# RS14100 register map
File version: 1.0
CPU: CM4 r0p1, little endian, MPU, FPU, 4 interrupt priority bits
Registers are 32-bit, read-write, reset 0x0 unless marked. A register's access mark holds for its fields unless they carry their own. Offsets are from the block's base; [hi:lo] are bit positions; lines under a group give offsets from that group; {n}, {i} and the like mark numbered series; 'fields as' and 'values as' point back to an identical list.

## MCPWM — The Motor Control PWM (MCPWM) controller is used to generate a periodic pulse waveform, which is useful in motor control and power control applications
Base 0x47070000
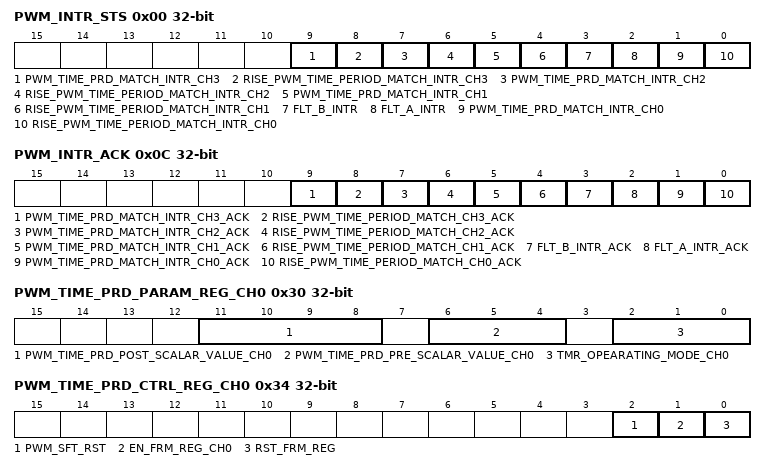
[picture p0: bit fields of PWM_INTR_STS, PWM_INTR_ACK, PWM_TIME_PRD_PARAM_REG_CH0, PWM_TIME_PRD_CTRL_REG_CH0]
0x00 PWM_INTR_STS ro — PWM Interrupt Status Register
  [9] PWM_TIME_PRD_MATCH_INTR_CH3 — This time base interrupt for 3rd channel, which considers postscaler value.
  [8] RISE_PWM_TIME_PERIOD_MATCH_INTR_CH3 — This time base interrupt for 3rd channel without considering postscaler value.
  [7] PWM_TIME_PRD_MATCH_INTR_CH2 — This time base interrupt for 2nd channel, which considers postscaler value
  [6] RISE_PWM_TIME_PERIOD_MATCH_INTR_CH2 — This time base interrupt for 2nd channel without considering postscaler value.
  [5] PWM_TIME_PRD_MATCH_INTR_CH1 — This time base interrupt for 1st channel, which considers postscaler value.
  [4] RISE_PWM_TIME_PERIOD_MATCH_INTR_CH1 — This time base interrupt for 1st channel without considering postscaler value
  [3] FLT_B_INTR — When the fault B pin is driven low, this interrupt is raised.
  [2] FLT_A_INTR — When the fault A pin is driven low, this interrupt is raised.
  [1] PWM_TIME_PRD_MATCH_INTR_CH0 — This time base interrupt for 0th channel, which considers postscaler value
  [0] RISE_PWM_TIME_PERIOD_MATCH_INTR_CH0 — This time base interrupt for 0th channel without considering postscaler
0x04 PWM_INTR_UNMASK — PWM Interrupt Unmask Register
  [15:0] PWM_INTR_UNMASK
0x08 PWM_INTR_MASK — PWM Interrupt mask Register
  [15:0] PWM_INTR_UNMASK
0x0C PWM_INTR_ACK — PWM Interrupt Acknowledgement Register
  [9] PWM_TIME_PRD_MATCH_INTR_CH3_ACK
    0=Disable (No effect); 1=Enable (pwm time period match interrupt for 3rd channel will be cleared)
  [8] RISE_PWM_TIME_PERIOD_MATCH_CH3_ACK
    values as PWM_TIME_PRD_MATCH_INTR_CH3_ACK
  [7] PWM_TIME_PRD_MATCH_INTR_CH2_ACK
    0=Disable (No effect); 1=Enable (pwm time period match interrupt for 2nd channel will be cleared.)
  [6] RISE_PWM_TIME_PERIOD_MATCH_CH2_ACK
    0=Disable (No effect); 1=Enable (pwm time period match interrupt for 2nd channel will be cleared)
  [5] PWM_TIME_PRD_MATCH_INTR_CH1_ACK
    0=Disable (No effect); 1=Enable (pwm time period match interrupt for 1st channel will be cleared.)
  [4] RISE_PWM_TIME_PERIOD_MATCH_CH1_ACK
    0=Disable (No effect); 1=Enable (pwm time period match interrupt for 1st channel will be cleared)
  [3] FLT_B_INTR_ACK
    0=Disable (No effect); 1=Enable (pwm faultB interrupt will be cleared.)
  [2] FLT_A_INTR_ACK
    0=Disable (No effect); 1=Enable (pwm faultA interrupt will be cleared)
  [1] PWM_TIME_PRD_MATCH_INTR_CH0_ACK
    0=Disable (No effect); 1=Enable (pwm time period match interrupt for 0th channel will be cleared)
  [0] RISE_PWM_TIME_PERIOD_MATCH_CH0_ACK
    0=Disable (No effect.); 1=Enable (PWM time period match interrupt for 0th channel will be cleared.)
0x28 PWM_TIME_PRD_WR_REG_CH0
  [15:0] WR_VALUE_CH0 — Value to update the base timer period register of channel 0
0x2C PWM_TIME_PRD_CNTR_WR_REG_CH0
  [15:0] WR_REG_CH0 — To update the base time counter initial value for channel 0
0x30 PWM_TIME_PRD_PARAM_REG_CH0
  [11:8] PWM_TIME_PRD_POST_SCALAR_VALUE_CH0 — Time base output post scale bits for channel0
    0=POST_SCALE1 (0000 1 to 1 post scale); 1=POST_SCALE2 (0001 1 to 2); 2=POST_SCALE3 (0010 1 to 3); 3=POST_SCALE4 (0011 1 to 4); 4=POST_SCALE5 (0100 1 to 5); 5=POST_SCALE6 (0101 1 to 6); 6=POST_SCALE7 (0110 1 to 7); 7=POST_SCALE8 (0111 1 to 8); 8=POST_SCALE9 (1000 1 to 9); 9=POST_SCALE10 (1001 1 to 10); 10=POST_SCALE11 (1010 1 to 11); 11=POST_SCALE12 (1011 1:12); 12=POST_SCALE13 (1100 1:13); 13=POST_SCALE14 (1101 1 to 14); 14=POST_SCALE15 (1110 1 to 15); 15=POST_SCALE16 (1111 1 to 16)
  [6:4] PWM_TIME_PRD_PRE_SCALAR_VALUE_CH0 — Base timer input clock pre scale select value for channel0.
    0=1X_INPUT_CLOCK (1x input clock period); 1=2X_INPUT_CLOCK (2x input clock period); 2=4X_INPUT_CLOCK (4x input clock period); 3=16X_INPUT_CLOCK (16x input clock period); 4=32X_INPUT_CLOCK (32x input clock period); 5=NONE1; 6=64X_INPUT_CLOCK (64x input clock period); 7=NONE2
  [2:0] TMR_OPEARATING_MODE_CH0 — Base timer operating mode for channel0
    0=FREE_RUNNING (free running mode); 1=SINGLE_EVENT (single event mode); 2=DOWN_COUNT (down count mode); 3=NONE; 4=UP_DOWN (up/down mode); 5=UP_DOWN_DOUBLE (up/down mode with interrupts for double PWM updates); 6=NONE1; 7=NONE2
0x34 PWM_TIME_PRD_CTRL_REG_CH0
  [2] PWM_SFT_RST — MC PWM soft reset
  [1] EN_FRM_REG_CH0 — Base timer enable for channnel0
    0=Disable (tiemr is disabled); 1=Enable (timer is enabled)
  [0] RST_FRM_REG — Time period counter soft reset
0x38 PWM_TIME_PRD_STS_REG_CH0
  [0] DIR_STS_CH0 — Time period counter direction status for channel0
0x3C PWM_TIME_PRD_CNTR_VALUE_CH0 ro
  [15:0] CNTR_VALUE_CH0 — Time period counter current value for channel0
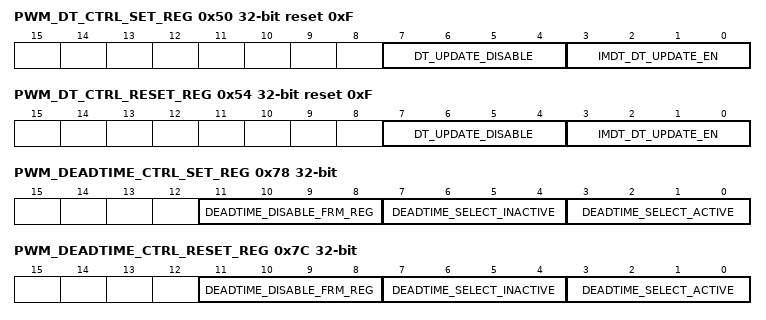
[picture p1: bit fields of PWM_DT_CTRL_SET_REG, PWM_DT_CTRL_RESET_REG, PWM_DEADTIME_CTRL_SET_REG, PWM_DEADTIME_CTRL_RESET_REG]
0x50 PWM_DT_CTRL_SET_REG reset 0xF
  [7:4] DT_UPDATE_DISABLE — Duty cycle register updation disable. There is a separate bit for each channel
  [3:0] IMDT_DT_UPDATE_EN — Enable to update the duty cycle immediately
0x54 PWM_DT_CTRL_RESET_REG reset 0xF
  [7:4] DT_UPDATE_DISABLE — Duty cycle register updation disable. There is a separate bit for each channel.
  [3:0] IMDT_DT_UPDATE_EN — Enable to update the duty cycle immediately
{0x58+4i} DUTYCYCLE[{i}] (i=0..3)
  [15:0] PWM_DC_REG_WR_VALUE_CH0 — Duty cycle value for channel0
0x78 PWM_DEADTIME_CTRL_SET_REG
  [11:8] DEADTIME_DISABLE_FRM_REG — Dead time counter soft reset for each channel.
  [7:4] DEADTIME_SELECT_INACTIVE — Dead time select bits for PWM going inactive
    0=Disable (means use counter A); 1=Enable (means use counter B)
  [3:0] DEADTIME_SELECT_ACTIVE — Dead time select bits for PWM going active
    values as DEADTIME_SELECT_INACTIVE
0x7C PWM_DEADTIME_CTRL_RESET_REG
  fields as PWM_DEADTIME_CTRL_SET_REG
0x80 PWM_DEADTIME_PRESCALE_SELECT_A
  [3:0] DEADTIME_PRESCALE_SELECT_A — Dead time prescale selection bits for unit A.
    0=clock period for dead time unit A is 1x input clock period; 1=clock period for dead time unit A is 2x input clock period; 2=means clock period for dead time unit A is 4x input clock period; 3=clock period for dead time unit A is 8x input clock period
0x84 PWM_DEADTIME_PRESCALE_SELECT_B
  [3:0] DEADTIME_PRESCALE_SELECT_B — Dead time prescale selection bits for unit B
    0=clock period for dead time unit B is 1x input clock period; 1=clock period for dead time unit B is 2x input clock period; 2=means clock period for dead time unit B is 4x input clock period; 3=clock period for dead time unit B is 8x input clock period
{0x88+4i} DEADTIME[{i}] (i=0..3) group
  0x00 PWM_DEADTIME_A_0
    [5:0] DEADTIME_A_CH0 — Dead time A value to load into dead time counter A of channel0
  0x04 PWM_DEADTIME_B_0
    [5:0] DEADTIME_B_CH0 — Dead time B value to load into deadtime counter B of channel0
0xC8 PWM_OP_OVERRIDE_CTRL_SET_REG
  [0] OP_OVERRIDE_SYNC — Output override is synced with pwm time period depending on operating mode
0xCC PWM_OP_OVERRIDE_CTRL_RESET_REG
  fields as PWM_OP_OVERRIDE_CTRL_SET_REG
0xD0 PWM_OP_OVERRIDE_ENABLE_SET_REG
  [7:0] PWM_OP_OVERRIDE_ENABLE_REG — Pwm output over ride enable
    {v}=L{v} ({v} bit for L{v}) (v=0..3); {v}=L{v} ({v} bit for H{v-4}) (v=4..7)
0xD4 PWM_OP_OVERRIDE_ENABLE_RESET_REG
  fields as PWM_OP_OVERRIDE_ENABLE_SET_REG
0xD8 PWM_OP_OVERRIDE_VALUE_SET_REG
  [7:0] OP_OVERRIDE_VALUE — Pwm output over ride value.
    values as PWM_OP_OVERRIDE_ENABLE_SET_REG.PWM_OP_OVERRIDE_ENABLE_REG
0xDC PWM_OP_OVERRIDE_VALUE_RESET_REG
  fields as PWM_OP_OVERRIDE_VALUE_SET_REG
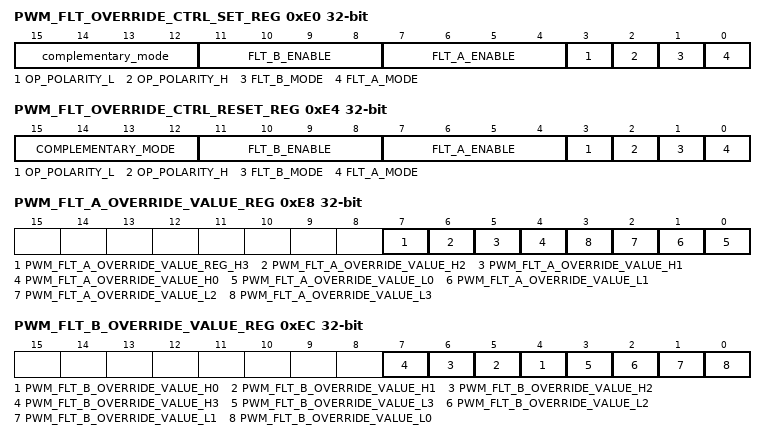
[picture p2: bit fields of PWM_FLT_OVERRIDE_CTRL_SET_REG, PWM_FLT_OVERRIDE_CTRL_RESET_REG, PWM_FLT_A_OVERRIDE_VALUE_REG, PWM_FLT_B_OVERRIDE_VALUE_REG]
0xE0 PWM_FLT_OVERRIDE_CTRL_SET_REG
  [15:12] complementary_mode — PWM I/O pair mode
    0=Disable (PWM I/O pin pair is in the independent output mode); 1=Enable (PWM I/O pin pair is in the complementary output mode)
  [11:8] FLT_B_ENABLE — Fault B enable. Separate enable bit is present for channel
  [7:4] FLT_A_ENABLE — Fault A enable. Separate enable bit is present for channel
  [3] OP_POLARITY_L — Ouput polarity for low (L3, L2, L1, L0) side signals.
    0=Disable (means active low mode); 1=Enable (means active high mode)
  [2] OP_POLARITY_H — Ouput polarity for high (H3, H2, H1, H0) side signals
    values as OP_POLARITY_L
  [1] FLT_B_MODE — Fault B mode
    0=Disable (latched mode); 1=Enable (cycle by cycle by mode)
  [0] FLT_A_MODE — Fault A mode
    0=Disable (latched mode); 1=Enable (cycle by cycle by mode)
0xE4 PWM_FLT_OVERRIDE_CTRL_RESET_REG (reset mask 0xFF)
  [15:12] COMPLEMENTARY_MODE — PWM I/O pair mode
    values as PWM_FLT_OVERRIDE_CTRL_SET_REG.complementary_mode
  [11:8] FLT_B_ENABLE — Fault B enable. Separate enable bit is present for channel
  [7:4] FLT_A_ENABLE — Fault A enable. Separate enable bit is present for channel
  [3] OP_POLARITY_L — Ouput polarity for low (L3, L2, L1, L0) side signals.
    values as PWM_FLT_OVERRIDE_CTRL_SET_REG.OP_POLARITY_L
  [2] OP_POLARITY_H — Ouput polarity for high (H3, H2, H1, H0) side signals
    values as PWM_FLT_OVERRIDE_CTRL_SET_REG.OP_POLARITY_L
  [1] FLT_B_MODE — Fault B mode
    0=Disable (latched mode); 1=Enable (cycle by cycle by mode)
  [0] FLT_A_MODE — Fault B mode
    0=Disable (latched mode); 1=Enable (cycle by cycle by mode)
0xE8 PWM_FLT_A_OVERRIDE_VALUE_REG — Fault input A PWM override value
  [7] PWM_FLT_A_OVERRIDE_VALUE_REG_H3 — 7 bit for H3
    0=inactive_A_H3 (0 means PWM output pin is driven inactive on an external fault input A event); 1=active_A_H3 (1 means PWM output pin is driven active on an external fault input A event.)
  [6] PWM_FLT_A_OVERRIDE_VALUE_H2 — 6 bit for H2
    0=inactive_A_H2 (0 means PWM output pin is driven inactive on an external fault input A event); 1=active_A_H2 (1 means PWM output pin is driven active on an external fault input A event.)
  [5] PWM_FLT_A_OVERRIDE_VALUE_H1 — 5 bit for H1
    0=inactive_A_H1 (0 means PWM output pin is driven inactive on an external fault input A event); 1=active_A_H1 (1 means PWM output pin is driven active on an external fault input A event.)
  [4] PWM_FLT_A_OVERRIDE_VALUE_H0 — 4 bit for H0
    0=inactive_A_H0 (0 means PWM output pin is driven inactive on an external fault input A event); 1=active_A_H0 (1 means PWM output pin is driven active on an external fault input A event.)
  [n] PWM_FLT_A_OVERRIDE_VALUE_L{n} (n=0..3) — {n} bit for L{n}
    0=inactive_A_L{n} (0 means PWM output pin is driven inactive on an external fault input A event); 1=active_A_L{n} (1 means PWM output pin is driven active on an external fault input A event.)
0xEC PWM_FLT_B_OVERRIDE_VALUE_REG — Fault input B PWM override value
  [n+4] PWM_FLT_B_OVERRIDE_VALUE_H{n} (n=0..3) — {n+4} bit for H{n}
    0=inactive_B_H{n} (0 means PWM output pin is driven inactive on an external fault input A event); 1=active_B_H{n} (1 means PWM output pin is driven active on an external fault input A event.)
  [3] PWM_FLT_B_OVERRIDE_VALUE_L3 — 3 bit for L3
    0=inactive_B_L3 (0 means PWM output pin is driven inactive on an external fault input A event); 1=active_B_L3 (1 means PWM output pin is driven active on an external fault input A event.)
  [2] PWM_FLT_B_OVERRIDE_VALUE_L2 — 2 bit for L2
    0=inactive_B_L2 (0 means PWM output pin is driven inactive on an external fault input A event); 1=active_B_L2 (1 means PWM output pin is driven active on an external fault input A event.)
  [1] PWM_FLT_B_OVERRIDE_VALUE_L1 — 1 bit for L1
    0=inactive_B_L1 (0 means PWM output pin is driven inactive on an external fault input A event); 1=active_B_L1 (1 means PWM output pin is driven active on an external fault input A event.)
  [0] PWM_FLT_B_OVERRIDE_VALUE_L0 — 0 bit for L0
    0=inactive_B_L0 (0 means PWM output pin is driven inactive on an external fault input B event); 1=active_B_L0 (1 means PWM output pin is driven active on an external fault input B event.)
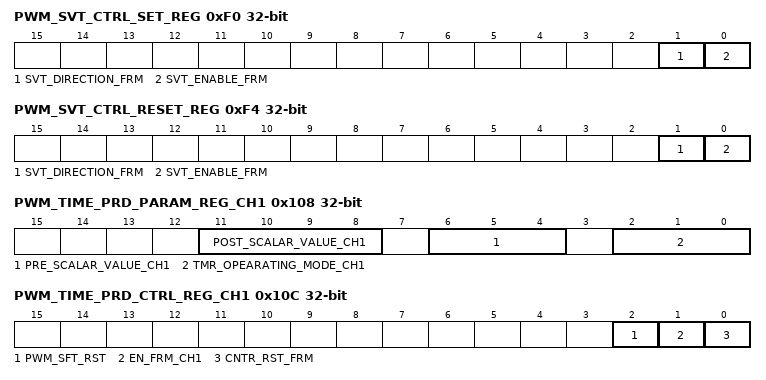
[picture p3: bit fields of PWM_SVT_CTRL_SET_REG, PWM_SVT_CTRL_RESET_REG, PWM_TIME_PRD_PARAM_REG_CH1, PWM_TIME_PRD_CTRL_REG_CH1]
0xF0 PWM_SVT_CTRL_SET_REG
  [1] SVT_DIRECTION_FRM — Special event trigger for time base direction
    0=COUNTING_UP (A special event trigger will occur when PWM time base is counting up); 1=COUNTING_DOWN (A special event trigger will occur when PWM time base is counting down)
  [0] SVT_ENABLE_FRM — Special event trigger enable. This is used to enable generation special event trigger
0xF4 PWM_SVT_CTRL_RESET_REG
  fields as PWM_SVT_CTRL_SET_REG
0xF8 PWM_SVT_PARAM_REG
  [3:0] SVT_ENABLE_FRM — Special event trigger enable. This is used to enable generation special event trigger
0xFC PWM_SVT_COMPARE_VALUE_REG
  [15:0] PWM_SVT_COMPARE_VALUE — Special event compare value. This is used to compare with pwm time period counter to generate special event trigger
0x100 PWM_TIME_PRD_WR_REG_CH1
  [15:0] WR_VALUE_CH1 — Value to update the base timer period register of channel 1
0x104 PWM_TIME_PRD_CNTR_WR_REG_CH1
  [15:0] WR_REG_CH1 — To update the base time counter initial value for channel 1
0x108 PWM_TIME_PRD_PARAM_REG_CH1 (reset mask 0xFF)
  [11:8] POST_SCALAR_VALUE_CH1 — Time base output post scale bits for channel1
    0=POST_SCALE_1 (0000 1:1 post scale); 1=POST_SCALE_2 (0001 1:2); 2=POST_SCALE_3 (0010 1:3); 3=POST_SCALE_4 (0011 1:4); 4=POST_SCALE_5 (0100 1:5); 5=POST_SCALE_6 (0101 1:6); 6=POST_SCALE_7 (0110 1:7); 7=POST_SCALE_8 (0111 1:8); 8=POST_SCALE_9 (1000 1:9); 9=POST_SCALE_10 (1001 1:10); 10=POST_SCALE_11 (1010 1:11); 11=POST_SCALE_12 (1011 1:12); 12=POST_SCALE_13 (1100 1:13); 13=POST_SCALE_14 (1101 1:14); 14=POST_SCALE_15 (1110 1:15); 15=POST_SCALE_16 (1111 1:16)
  [6:4] PRE_SCALAR_VALUE_CH1 — Base timer input clock prescale select value for channel1.
    values as PWM_TIME_PRD_PARAM_REG_CH0.PWM_TIME_PRD_PRE_SCALAR_VALUE_CH0
  [2:0] TMR_OPEARATING_MODE_CH1 — Base timer operating mode for channel1
    0=FREE_RUNNING (free running mode); 1=SINGLE_EVENT (single event mode); 2=DOWN_COUNT (down count mode); 3=NONE; 4=UP_DOWN (up/down mode); 5=UP_DOWN_DOUBLE (up/dowm mode with interrupts for double PWM updates); 6=NONE1; 7=NONE2
0x10C PWM_TIME_PRD_CTRL_REG_CH1
  [2] PWM_SFT_RST — MC PWM soft reset
  [1] EN_FRM_CH1 — Base timer enable for channnel1
    0=disable (timer is disabled); 1=enable (timer is enabled)
  [0] CNTR_RST_FRM — Time period counter soft reset
0x110 PWM_TIME_PRD_STS_REG_CH1
  [0] DIR_STS_CH1 — Time period counter direction status for channel1.
    0=downword (downward); 1=upword (upward)
0x114 PWM_TIME_PRD_CNTR_VALUE_CH1
  [0] PWM_TIME_PRD_CNTR_VALUE_CH1 — Time period counter current value for channel1
0x118 PWM_TIME_PRD_WR_REG_CH2
  [0] WR_VALUE_CH2 — Value to update the base timer period register of channel 2
0x11C PWM_TIME_PRD_CNTR_WR_REG_CH2
  [0] CNTR_WR_REG_CH2 — To update the base time counter initial value for channel 2
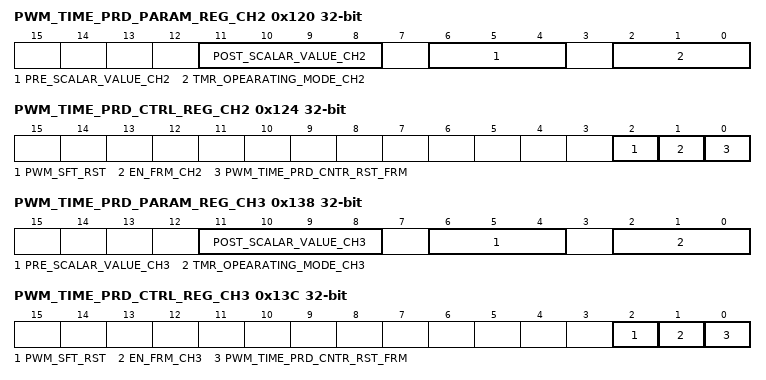
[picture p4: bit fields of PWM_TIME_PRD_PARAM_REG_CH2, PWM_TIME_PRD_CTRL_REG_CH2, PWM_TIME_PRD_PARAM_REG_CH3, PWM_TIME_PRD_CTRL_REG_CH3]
0x120 PWM_TIME_PRD_PARAM_REG_CH2
  [11:8] POST_SCALAR_VALUE_CH2 — Time base output post scale bits for channel2
    0=POST_SCALE1 (0000 1:1 post scale); 1=POST_SCALE2 (0001 1:2); 2=POST_SCALE3 (0010 1:3); 3=POST_SCALE4 (0011 1:4); 4=POST_SCALE5 (0100 1:5); 5=POST_SCALE6 (0101 1:6); 6=POST_SCALE7 (0110 1:7); 7=POST_SCALE8 (0111 1:8); 8=POST_SCALE9 (1000 1:9); 9=POST_SCALE10 (1001 1:10); 10=POST_SCALE11 (1010 1:11); 11=POST_SCALE12 (1011 1:12); 12=POST_SCALE13 (1100 1:13); 13=POST_SCALE14 (1101 1:14); 14=POST_SCALE15 (1110 1:15); 15=POST_SCALE16 (1111 1:16)
  [6:4] PRE_SCALAR_VALUE_CH2 — Base timer input clock pre scale select value for channel2.
    0=1X_INPUT_CLOCK (1x input clock period); 1=2X_INPUT_CLOCK (2x input clock period); 2=4X_INPUT_CLOCK (4x input clock period); 3=16X_INPUT_CLOCK (16x input clock period); 4=32X_INPUT_CLOCK (32x input clock period); 5=NONE; 6=64X_INPUT_CLOCK (64x input clock period); 7=NONE1
  [2:0] TMR_OPEARATING_MODE_CH2 — Base timer operating mode for channel2
    values as PWM_TIME_PRD_PARAM_REG_CH0.TMR_OPEARATING_MODE_CH0
0x124 PWM_TIME_PRD_CTRL_REG_CH2
  [2] PWM_SFT_RST — MC PWM soft reset
  [1] EN_FRM_CH2 — Base timer enable for channnel2
    0=disable (timer is disabled); 1=enable (timer is enabled)
  [0] PWM_TIME_PRD_CNTR_RST_FRM — Time period counter soft reset
0x128 PWM_TIME_PRD_STS_REG_CH2
  [0] DIR_STS_CH2 — Time period counter direction status for channel2.
    0=downward; 1=upward
0x12C PWM_TIME_PRD_CNTR_VALUE_CH2
  [0] CNTR_VALUE_CH2 — Time period counter current value for channel3
0x130 PWM_TIME_PRD_WR_REG_CH3
  [15:0] WR_VALUE_CH3 — To update the base time counter initial value for channel 3
0x134 PWM_TIME_PRD_CNTR_WR_REG_CH3
  [15:0] WR_VALUE_CH3 — Value to update the base timer period register of channel 3
0x138 PWM_TIME_PRD_PARAM_REG_CH3
  [11:8] POST_SCALAR_VALUE_CH3 — Time base output post scale bits for channel3
    values as PWM_TIME_PRD_PARAM_REG_CH2.POST_SCALAR_VALUE_CH2
  [6:4] PRE_SCALAR_VALUE_CH3 — Base timer input clock pre scale select value for channel2.
    0=1X_INPUT_CLOCK (1x input clock period); 1=2X_INPUT_CLOCK (2x input clock period); 2=4X_INPUT_CLOCK (4x input clock period); 3=16X_INPUT_CLOCK (16x input clock period); 4=32X_INPUT_CLOCK (32x input clock period); 5=NONE; 6=64X_INPUT_CLOCK (64x input clock period); 7=NONE2
  [2:0] TMR_OPEARATING_MODE_CH3 — Base timer operating mode for channel3
    values as PWM_TIME_PRD_PARAM_REG_CH0.TMR_OPEARATING_MODE_CH0
0x13C PWM_TIME_PRD_CTRL_REG_CH3
  [2] PWM_SFT_RST — MC PWM soft reset
  [1] EN_FRM_CH3 — Base timer enable for channnel3
    0=disable (timer is disabled); 1=enable (timer is enabled)
  [0] PWM_TIME_PRD_CNTR_RST_FRM — Time period counter soft reset
0x140 PWM_TIME_PRD_STS_REG_CH3
  [0] DIR_STS_CH3 — Time period counter direction status for channel3.
    0=downword (downward); 1=upward
0x144 PWM_TIME_PRD_CNTR_VALUE_CH3 (reset mask 0x1)
  [15:0] CNTR_VALUE_CH3 — Time period counter current value for channe3
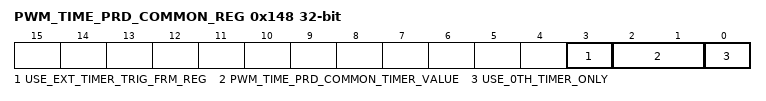
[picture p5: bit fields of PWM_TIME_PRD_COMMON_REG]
0x148 PWM_TIME_PRD_COMMON_REG (reset mask 0x1)
  [3] USE_EXT_TIMER_TRIG_FRM_REG — Enable to use external trigger for base time counter increment or decrement.
  [2:1] PWM_TIME_PRD_COMMON_TIMER_VALUE — Base timers select to generate special event trigger
  [0] USE_0TH_TIMER_ONLY — Instead of use four base timers for four channels, use only one base timer for all channels.
    0=ONE_FOR_ONE_CHANNEL (one base timer for each channel); 1=ONE_FOR_ALL_CHANNEL (only one base timer for all channels)
